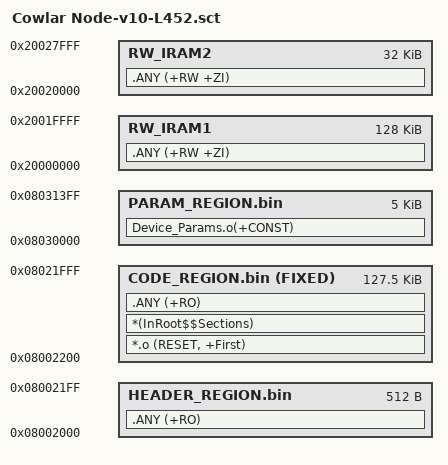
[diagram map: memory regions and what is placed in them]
; *************************************************************
; *** Scatter-Loading Description File generated by uVision ***
; *************************************************************


; when change something update this file as well "Flash_Memory_Map.h"


LR_IROM1            0x08002000 0x00020000  {    ; load region size_region
  HEADER_REGION.bin 0x08002000 0x00000200  {    ; load address = execution address
   .ANY (+RO)
  } 
  CODE_REGION.bin   0x08002200 FIXED (0x0001AE00 + 0x00005000)  {    ; load address = execution address
   *.o (RESET, +First)
   *(InRoot$$Sections)
   .ANY (+RO)
  }
  ;ANN_REGION.bin    0x0801D000 0x00005000  {
    ;behavior_ANN.o(+CONST)
    ;walking_ANN.o(+CONST)
  ;}

  RW_IRAM1          0x20000000 0x00020000  {    ; RW data
   .ANY (+RW +ZI)
  }
  RW_IRAM2          0x20020000 0x00008000  {    ; RW data
   .ANY (+RW +ZI)
  }
}

LR_IROM2            0x08030000 0x00001400  {    ; load region size_region

  PARAM_REGION.bin  0x08030000 0x00001400  {
    Device_Params.o(+CONST)
  }
}
